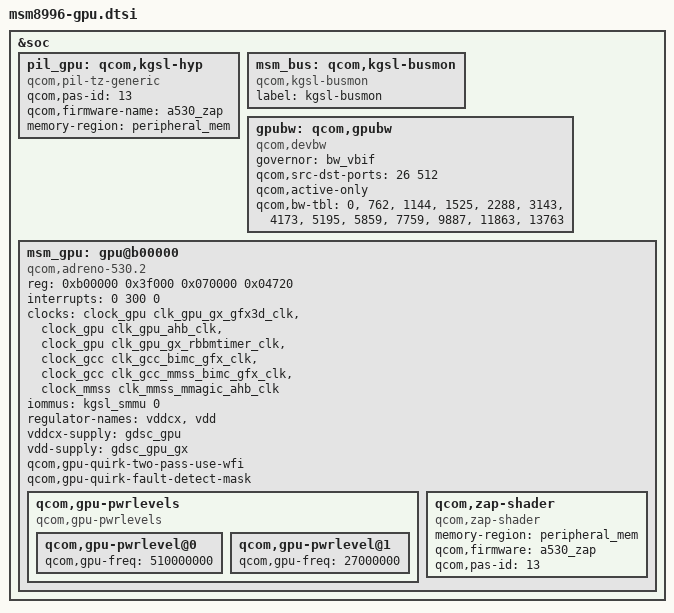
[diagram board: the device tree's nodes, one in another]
/* Copyright (c) 2015, The Linux Foundation. All rights reserved.
 *
 * This program is free software; you can redistribute it and/or modify
 * it under the terms of the GNU General Public License version 2 and
 * only version 2 as published by the Free Software Foundation.
 *
 * This program is distributed in the hope that it will be useful,
 * but WITHOUT ANY WARRANTY; without even the implied warranty of
 * MERCHANTABILITY or FITNESS FOR A PARTICULAR PURPOSE.  See the
 * GNU General Public License for more details.
 */

&soc {

	pil_gpu: qcom,kgsl-hyp {
		compatible = "qcom,pil-tz-generic";
		qcom,pas-id = <13>;
		qcom,firmware-name = "a530_zap";
		memory-region = <&peripheral_mem>;
	};

	msm_bus: qcom,kgsl-busmon{
		label = "kgsl-busmon";
		compatible = "qcom,kgsl-busmon";
	};

	gpubw: qcom,gpubw {
		compatible = "qcom,devbw";
		governor = "bw_vbif";
		qcom,src-dst-ports = <26 512>;
		/*
		 * active-only flag is used while registering the bus
		 * governor.It helps release the bus vote when the CPU
		 * subsystem is inactiv3
		 */
		qcom,active-only;
		qcom,bw-tbl =
			<     0 /*  off     */ >,
			<   762 /*  100 MHz */ >,
			<  1144 /*  150 MHz */ >,
			<  1525 /*  200 MHz */ >,
			<  2288 /*  300 MHz */ >,
			<  3143 /*  412 MHz */ >,
			<  4173 /*  547 MHz */ >,
			<  5195 /*  681 MHz */ >,
			<  5859 /*  768 MHz */ >,
			<  7759 /*  1017 MHz */ >,
			<  9887 /*  1296 MHz */ >,
			<  11863 /*  1555 MHz */ >,
			<  13763 /*  1804 MHz */ >;
	};

	msm_gpu: gpu@b00000 {
			compatible = "qcom,adreno-530.2", "qcom,adreno";
			status = "ok";
			reg = <0xb00000 0x3f000
			       0x070000 0x04720>;
			reg-names = "kgsl_3d0_reg_memory", "qfprom_memory";
			interrupts = <0 300 0>;
			interrupt-names = "kgsl_3d0_irq";

			clocks = <&clock_gpu clk_gpu_gx_gfx3d_clk>,
				<&clock_gpu clk_gpu_ahb_clk>,
				<&clock_gpu clk_gpu_gx_rbbmtimer_clk>,
				<&clock_gcc clk_gcc_bimc_gfx_clk>,
				<&clock_gcc clk_gcc_mmss_bimc_gfx_clk>,
				<&clock_mmss clk_mmss_mmagic_ahb_clk>;

			clock-names = "core", "iface", "rbbmtimer",
				"mem", "mem_iface", "alt_mem_iface";

			iommus = <&kgsl_smmu 0>;
			/* GDSC regulator names */
			regulator-names = "vddcx", "vdd";
			/* GDSC oxili regulators */
			vddcx-supply = <&gdsc_gpu>;
			vdd-supply = <&gdsc_gpu_gx>;
			qcom,gpu-quirk-two-pass-use-wfi;
			qcom,gpu-quirk-fault-detect-mask;
			/* This is a safe speed for bring up in all bin levels.
			 * This isn't the fastest the chip can go, but we can
			 * get there eventually */
			qcom,gpu-pwrlevels {
				compatible = "qcom,gpu-pwrlevels";
				qcom,gpu-pwrlevel@0 {
					qcom,gpu-freq = <510000000>;
				};
				qcom,gpu-pwrlevel@1 {
					qcom,gpu-freq = <27000000>;
				};
			};

			qcom,zap-shader {
				compatible = "qcom,zap-shader";
				memory-region = <&peripheral_mem>;

				qcom,firmware = "a530_zap";
				qcom,pas-id = <13>;
			};

	};

};
